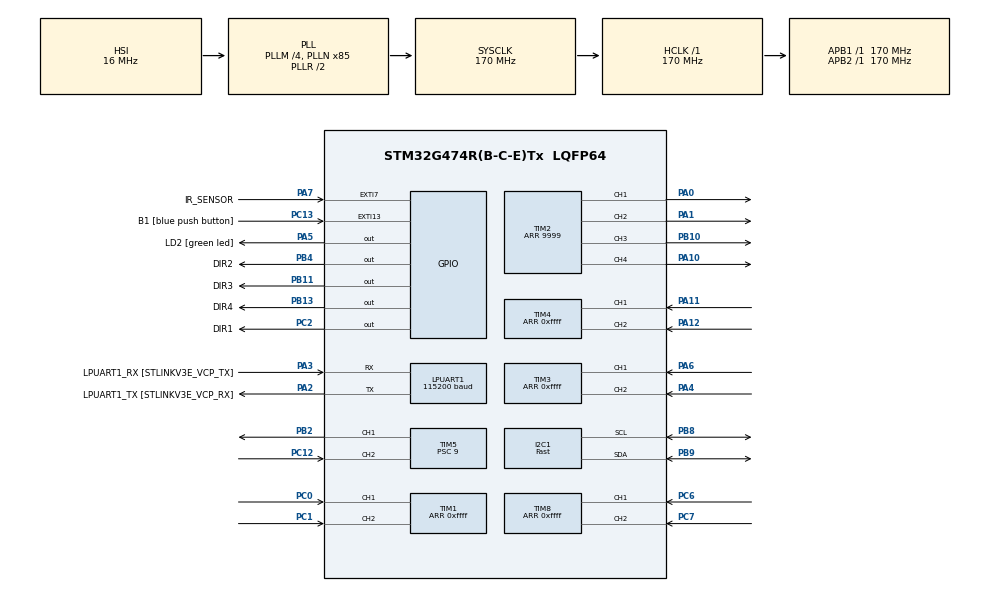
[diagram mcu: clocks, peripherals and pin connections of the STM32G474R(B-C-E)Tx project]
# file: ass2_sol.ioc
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I2C1.I2C_Speed_Mode=I2C_Fast
I2C1.Timing=0x40621236
LPUART1.BaudRate=115200
Mcu.Family=STM32G4
Mcu.Name=STM32G474R(B-C-E)Tx
Mcu.Package=LQFP64
NVIC.EXTI15_10_IRQn=true\:0\:0\:false\:false\:true\:true\:true\:true
NVIC.EXTI9_5_IRQn=true\:0\:0\:false\:false\:true\:true\:true\:true
NVIC.PriorityGroup=NVIC_PRIORITYGROUP_4
NVIC.TIM2_IRQn=true\:0\:0\:false\:false\:true\:true\:true\:true
NVIC.TIM5_IRQn=true\:0\:0\:false\:false\:true\:true\:true\:true
NVIC.TIM6_DAC_IRQn=true\:0\:0\:false\:false\:true\:true\:true\:true
NVIC.TIM7_DAC_IRQn=true\:0\:0\:false\:false\:true\:true\:true\:true
PA0.Signal=S_TIM2_CH1
PA1.Signal=S_TIM2_CH2
PA10.Signal=S_TIM2_CH4
PA11.Signal=S_TIM4_CH1
PA12.Signal=S_TIM4_CH2
PA13.GPIO_Label=T_SWDIO
PA13.Mode=Serial_Wire
PA13.Signal=SYS_JTMS-SWDIO
PA14.GPIO_Label=T_SWCLK
PA14.Mode=Serial_Wire
PA14.Signal=SYS_JTCK-SWCLK
PA2.GPIO_Label=LPUART1_TX [STLINKV3E_VCP_RX]
PA2.Mode=Asynchronous
PA2.Signal=LPUART1_TX
PA3.GPIO_Label=LPUART1_RX [STLINKV3E_VCP_TX]
PA3.Mode=Asynchronous
PA3.Signal=LPUART1_RX
PA4.Signal=S_TIM3_CH2
PA5.GPIO_Label=LD2 [green led]
PA5.Signal=GPIO_Output
PA6.Signal=S_TIM3_CH1
PA7.GPIO_Label=IR_SENSOR
PA7.GPIO_ModeDefaultEXTI=GPIO_MODE_IT_RISING_FALLING
PA7.Signal=GPXTI7
PB10.Signal=S_TIM2_CH3
PB11.GPIO_Label=DIR3
PB11.Signal=GPIO_Output
PB13.GPIO_Label=DIR4
PB13.Signal=GPIO_Output
PB2.Signal=S_TIM5_CH1
PB3.GPIO_Label=T_SWO
PB3.Signal=SYS_JTDO-SWO
PB4.GPIO_Label=DIR2
PB4.Signal=GPIO_Output
PB8-BOOT0.Mode=I2C
PB8-BOOT0.Signal=I2C1_SCL
PB9.Mode=I2C
PB9.Signal=I2C1_SDA
PC0.Signal=S_TIM1_CH1
PC1.Signal=S_TIM1_CH2
PC12.Signal=S_TIM5_CH2
PC13.GPIO_Label=B1 [blue push button]
PC13.Signal=GPXTI13
PC14-OSC32_IN.Mode=LSE-External-Oscillator
PC14-OSC32_IN.Signal=RCC_OSC32_IN
PC15-OSC32_OUT.Mode=LSE-External-Oscillator
PC15-OSC32_OUT.Signal=RCC_OSC32_OUT
PC2.GPIO_Label=DIR1
PC2.Signal=GPIO_Output
PC6.Signal=S_TIM8_CH1
PC7.Signal=S_TIM8_CH2
PF0-OSC_IN.Mode=HSE-External-Oscillator
PF0-OSC_IN.Signal=RCC_OSC_IN
PF1-OSC_OUT.Mode=HSE-External-Oscillator
PF1-OSC_OUT.Signal=RCC_OSC_OUT
ProjectManager.HeapSize=0x200
ProjectManager.StackSize=0x400
ProjectManager.TargetToolchain=STM32CubeIDE
RCC.ADC12Freq_Value=170000000
RCC.ADC345Freq_Value=170000000
RCC.AHBFreq_Value=170000000
RCC.APB1Freq_Value=170000000
RCC.APB1TimFreq_Value=170000000
RCC.APB2Freq_Value=170000000
RCC.APB2TimFreq_Value=170000000
RCC.CortexFreq_Value=170000000
RCC.EXTERNAL_CLOCK_VALUE=12288000
RCC.HCLKFreq_Value=170000000
RCC.HSE_VALUE=24000000
RCC.HSI48_VALUE=48000000
RCC.HSI_VALUE=16000000
RCC.PLLM=RCC_PLLM_DIV4
RCC.PLLN=85
RCC.RTCClockSelection=RCC_RTCCLKSOURCE_LSE
RCC.SYSCLKFreq_VALUE=170000000
RCC.SYSCLKSource=RCC_SYSCLKSOURCE_PLLCLK
RCC.USBFreq_Value=170000000
RCC.VCOOutputFreq_Value=340000000
SH.S_TIM1_CH1.0=TIM1_CH1,Encoder_Interface
SH.S_TIM1_CH2.0=TIM1_CH2,Encoder_Interface
SH.S_TIM2_CH1.0=TIM2_CH1,PWM Generation1 CH1
SH.S_TIM2_CH2.0=TIM2_CH2,PWM Generation2 CH2
SH.S_TIM2_CH3.0=TIM2_CH3,PWM Generation3 CH3
SH.S_TIM2_CH4.0=TIM2_CH4,PWM Generation4 CH4
SH.S_TIM3_CH1.0=TIM3_CH1,Encoder_Interface
SH.S_TIM3_CH2.0=TIM3_CH2,Encoder_Interface
SH.S_TIM4_CH1.0=TIM4_CH1,Encoder_Interface
SH.S_TIM4_CH2.0=TIM4_CH2,Encoder_Interface
SH.S_TIM5_CH1.0=TIM5_CH1,PWM Generation1 CH1
SH.S_TIM5_CH2.0=TIM5_CH2,Input_Capture2_from_TI2
SH.S_TIM8_CH1.0=TIM8_CH1,Encoder_Interface
SH.S_TIM8_CH2.0=TIM8_CH2,Encoder_Interface
TIM1.PeriodNoDither=0xffff
TIM2.Channel-PWM\ Generation1\ CH1=TIM_CHANNEL_1
TIM2.Channel-PWM\ Generation2\ CH2=TIM_CHANNEL_2
TIM2.Channel-PWM\ Generation3\ CH3=TIM_CHANNEL_3
TIM2.Channel-PWM\ Generation4\ CH4=TIM_CHANNEL_4
TIM2.PeriodNoDither=9999
TIM3.PeriodNoDither=0xffff
TIM4.PeriodNoDither=0xffff
TIM5.Channel-Input_Capture2_from_TI2=TIM_CHANNEL_2
TIM5.Channel-PWM\ Generation1\ CH1=TIM_CHANNEL_1
TIM5.ICPolarity_CH2=TIM_INPUTCHANNELPOLARITY_BOTHEDGE
TIM5.PeriodNoDither=1699999
TIM5.Prescaler=9
TIM5.Pulse-PWM\ Generation1\ CH1=170
TIM6.Period=9999
TIM6.Prescaler=169
TIM7.Period=99
TIM7.Prescaler=169
TIM8.PeriodNoDither=0xffff
VP_SYS_VS_DBSignals.Mode=DisableDeadBatterySignals
VP_TIM2_VS_ClockSourceINT.Mode=Internal
VP_TIM5_VS_ClockSourceINT.Mode=Internal
VP_TIM6_VS_ClockSourceINT.Mode=Enable_Timer
VP_TIM7_VS_ClockSourceINT.Mode=Enable_Timer
board=NUCLEO-G474RE

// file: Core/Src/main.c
/* USER CODE BEGIN Header */
/**
  ******************************************************************************
  * @file           : main.c
  * @brief          : Main program body
  ******************************************************************************
  * @attention
  *
  * Copyright (c) 2026 STMicroelectronics.
  * All rights reserved.
  *
  * This software is licensed under terms that can be found in the LICENSE file
  * in the root directory of this software component.
  * If no LICENSE file comes with this software, it is provided AS-IS.
  *
  ******************************************************************************
  */
/* USER CODE END Header */
#include "main.h"

/* USER CODE BEGIN Includes */
#include <stdio.h>
#include "io_board.h"
#include "sonar.h"
#include "ass2.h"
/* USER CODE END Includes */

I2C_HandleTypeDef hi2c1;

UART_HandleTypeDef hlpuart1;

TIM_HandleTypeDef htim1;
TIM_HandleTypeDef htim2;
TIM_HandleTypeDef htim3;
TIM_HandleTypeDef htim4;
TIM_HandleTypeDef htim5;
TIM_HandleTypeDef htim6;
TIM_HandleTypeDef htim7;
TIM_HandleTypeDef htim8;

/* USER CODE BEGIN PV */
volatile uint16_t task = 0;   /* the task that runs: change it in Live Expressions */
/* USER CODE END PV */

void SystemClock_Config(void);
static void MX_GPIO_Init(void);
static void MX_I2C1_Init(void);
static void MX_LPUART1_UART_Init(void);
static void MX_TIM1_Init(void);
static void MX_TIM2_Init(void);
static void MX_TIM3_Init(void);
static void MX_TIM4_Init(void);
static void MX_TIM5_Init(void);
static void MX_TIM6_Init(void);
static void MX_TIM7_Init(void);
static void MX_TIM8_Init(void);

/* USER CODE BEGIN 0 */
/* printf -> LPUART1 (ST-LINK virtual COM port), as in tutorial 2:
   _write() in syscalls.c calls this once per character             */
int __io_putchar(int ch)
{
  HAL_UART_Transmit(&hlpuart1, (uint8_t *)&ch, 1, HAL_MAX_DELAY);
  return ch;
}
/* USER CODE END 0 */

int main(void)
{

  /* MCU Configuration--------------------------------------------------------*/

  /* Reset of all peripherals, Initializes the Flash interface and the Systick. */
  HAL_Init();

  /* Configure the system clock */
  SystemClock_Config();

  /* Initialize all configured peripherals */
  MX_GPIO_Init();
  MX_I2C1_Init();
  MX_LPUART1_UART_Init();
  MX_TIM1_Init();
  MX_TIM2_Init();
  MX_TIM3_Init();
  MX_TIM4_Init();
  MX_TIM5_Init();
  MX_TIM6_Init();
  MX_TIM7_Init();
  MX_TIM8_Init();
  /* USER CODE BEGIN 2 */
  ass2Init();       /* IO board, motor PWM at 0, IR interrupt off, menu */
  /* USER CODE END 2 */

  /* Infinite loop */
  while (1)
  {

    /* USER CODE BEGIN 3 */
    ass2Run();        /* runs the task chosen in `task` until it changes */
  }
  /* USER CODE END 3 */
}

void SystemClock_Config(void)
{
  RCC_OscInitTypeDef RCC_OscInitStruct = {0};
  RCC_ClkInitTypeDef RCC_ClkInitStruct = {0};

  /** Configure the main internal regulator output voltage
  */
  HAL_PWREx_ControlVoltageScaling(PWR_REGULATOR_VOLTAGE_SCALE1_BOOST);

  /** Initializes the RCC Oscillators according to the specified parameters
  * in the RCC_OscInitTypeDef structure.
  */
  RCC_OscInitStruct.OscillatorType = RCC_OSCILLATORTYPE_HSI;
  RCC_OscInitStruct.HSIState = RCC_HSI_ON;
  RCC_OscInitStruct.HSICalibrationValue = RCC_HSICALIBRATION_DEFAULT;
  RCC_OscInitStruct.PLL.PLLState = RCC_PLL_ON;
  RCC_OscInitStruct.PLL.PLLSource = RCC_PLLSOURCE_HSI;
  RCC_OscInitStruct.PLL.PLLM = RCC_PLLM_DIV4;
  RCC_OscInitStruct.PLL.PLLN = 85;
  RCC_OscInitStruct.PLL.PLLP = RCC_PLLP_DIV2;
  RCC_OscInitStruct.PLL.PLLQ = RCC_PLLQ_DIV2;
  RCC_OscInitStruct.PLL.PLLR = RCC_PLLR_DIV2;
  if (HAL_RCC_OscConfig(&RCC_OscInitStruct) != HAL_OK)
  {
    Error_Handler();
  }

  /** Initializes the CPU, AHB and APB buses clocks
  */
  RCC_ClkInitStruct.ClockType = RCC_CLOCKTYPE_HCLK|RCC_CLOCKTYPE_SYSCLK
                              |RCC_CLOCKTYPE_PCLK1|RCC_CLOCKTYPE_PCLK2;
  RCC_ClkInitStruct.SYSCLKSource = RCC_SYSCLKSOURCE_PLLCLK;
  RCC_ClkInitStruct.AHBCLKDivider = RCC_SYSCLK_DIV1;
  RCC_ClkInitStruct.APB1CLKDivider = RCC_HCLK_DIV1;
  RCC_ClkInitStruct.APB2CLKDivider = RCC_HCLK_DIV1;

  if (HAL_RCC_ClockConfig(&RCC_ClkInitStruct, FLASH_LATENCY_4) != HAL_OK)
  {
    Error_Handler();
  }
}

static void MX_I2C1_Init(void)
{

  hi2c1.Instance = I2C1;
  hi2c1.Init.Timing = 0x40621236;
  hi2c1.Init.OwnAddress1 = 0;
  hi2c1.Init.AddressingMode = I2C_ADDRESSINGMODE_7BIT;
  hi2c1.Init.DualAddressMode = I2C_DUALADDRESS_DISABLE;
  hi2c1.Init.OwnAddress2 = 0;
  hi2c1.Init.OwnAddress2Masks = I2C_OA2_NOMASK;
  hi2c1.Init.GeneralCallMode = I2C_GENERALCALL_DISABLE;
  hi2c1.Init.NoStretchMode = I2C_NOSTRETCH_DISABLE;
  if (HAL_I2C_Init(&hi2c1) != HAL_OK)
  {
    Error_Handler();
  }

  /** Configure Analogue filter
  */
  if (HAL_I2CEx_ConfigAnalogFilter(&hi2c1, I2C_ANALOGFILTER_ENABLE) != HAL_OK)
  {
    Error_Handler();
  }

  /** Configure Digital filter
  */
  if (HAL_I2CEx_ConfigDigitalFilter(&hi2c1, 0) != HAL_OK)
  {
    Error_Handler();
  }

}

static void MX_LPUART1_UART_Init(void)
{

  hlpuart1.Instance = LPUART1;
  hlpuart1.Init.BaudRate = 115200;
  hlpuart1.Init.WordLength = UART_WORDLENGTH_8B;
  hlpuart1.Init.StopBits = UART_STOPBITS_1;
  hlpuart1.Init.Parity = UART_PARITY_NONE;
  hlpuart1.Init.Mode = UART_MODE_TX_RX;
  hlpuart1.Init.HwFlowCtl = UART_HWCONTROL_NONE;
  hlpuart1.Init.OneBitSampling = UART_ONE_BIT_SAMPLE_DISABLE;
  hlpuart1.Init.ClockPrescaler = UART_PRESCALER_DIV1;
  hlpuart1.AdvancedInit.AdvFeatureInit = UART_ADVFEATURE_NO_INIT;
  if (HAL_UART_Init(&hlpuart1) != HAL_OK)
  {
    Error_Handler();
  }
  if (HAL_UARTEx_SetTxFifoThreshold(&hlpuart1, UART_TXFIFO_THRESHOLD_1_8) != HAL_OK)
  {
    Error_Handler();
  }
  if (HAL_UARTEx_SetRxFifoThreshold(&hlpuart1, UART_RXFIFO_THRESHOLD_1_8) != HAL_OK)
  {
    Error_Handler();
  }
  if (HAL_UARTEx_DisableFifoMode(&hlpuart1) != HAL_OK)
  {
    Error_Handler();
  }

}

static void MX_TIM1_Init(void)
{

  TIM_Encoder_InitTypeDef sConfig = {0};
  TIM_MasterConfigTypeDef sMasterConfig = {0};

  htim1.Instance = TIM1;
  htim1.Init.Prescaler = 0;
  htim1.Init.CounterMode = TIM_COUNTERMODE_UP;
  htim1.Init.Period = 65535;
  htim1.Init.ClockDivision = TIM_CLOCKDIVISION_DIV1;
  htim1.Init.RepetitionCounter = 0;
  htim1.Init.AutoReloadPreload = TIM_AUTORELOAD_PRELOAD_DISABLE;
  sConfig.EncoderMode = TIM_ENCODERMODE_TI1;
  sConfig.IC1Polarity = TIM_ICPOLARITY_RISING;
  sConfig.IC1Selection = TIM_ICSELECTION_DIRECTTI;
  sConfig.IC1Prescaler = TIM_ICPSC_DIV1;
  sConfig.IC1Filter = 0;
  sConfig.IC2Polarity = TIM_ICPOLARITY_RISING;
  sConfig.IC2Selection = TIM_ICSELECTION_DIRECTTI;
  sConfig.IC2Prescaler = TIM_ICPSC_DIV1;
  sConfig.IC2Filter = 0;
  if (HAL_TIM_Encoder_Init(&htim1, &sConfig) != HAL_OK)
  {
    Error_Handler();
  }
  sMasterConfig.MasterOutputTrigger = TIM_TRGO_RESET;
  sMasterConfig.MasterOutputTrigger2 = TIM_TRGO2_RESET;
  sMasterConfig.MasterSlaveMode = TIM_MASTERSLAVEMODE_DISABLE;
  if (HAL_TIMEx_MasterConfigSynchronization(&htim1, &sMasterConfig) != HAL_OK)
  {
    Error_Handler();
  }

}

static void MX_TIM2_Init(void)
{

  TIM_ClockConfigTypeDef sClockSourceConfig = {0};
  TIM_MasterConfigTypeDef sMasterConfig = {0};
  TIM_OC_InitTypeDef sConfigOC = {0};

  htim2.Instance = TIM2;
  htim2.Init.Prescaler = 0;
  htim2.Init.CounterMode = TIM_COUNTERMODE_UP;
  htim2.Init.Period = 9999;
  htim2.Init.ClockDivision = TIM_CLOCKDIVISION_DIV1;
  htim2.Init.AutoReloadPreload = TIM_AUTORELOAD_PRELOAD_DISABLE;
  if (HAL_TIM_Base_Init(&htim2) != HAL_OK)
  {
    Error_Handler();
  }
  sClockSourceConfig.ClockSource = TIM_CLOCKSOURCE_INTERNAL;
  if (HAL_TIM_ConfigClockSource(&htim2, &sClockSourceConfig) != HAL_OK)
  {
    Error_Handler();
  }
  if (HAL_TIM_PWM_Init(&htim2) != HAL_OK)
  {
    Error_Handler();
  }
  sMasterConfig.MasterOutputTrigger = TIM_TRGO_RESET;
  sMasterConfig.MasterSlaveMode = TIM_MASTERSLAVEMODE_DISABLE;
  if (HAL_TIMEx_MasterConfigSynchronization(&htim2, &sMasterConfig) != HAL_OK)
  {
    Error_Handler();
  }
  sConfigOC.OCMode = TIM_OCMODE_PWM1;
  sConfigOC.Pulse = 0;
  sConfigOC.OCPolarity = TIM_OCPOLARITY_HIGH;
  sConfigOC.OCFastMode = TIM_OCFAST_DISABLE;
  if (HAL_TIM_PWM_ConfigChannel(&htim2, &sConfigOC, TIM_CHANNEL_1) != HAL_OK)
  {
    Error_Handler();
  }
  if (HAL_TIM_PWM_ConfigChannel(&htim2, &sConfigOC, TIM_CHANNEL_2) != HAL_OK)
  {
    Error_Handler();
  }
  if (HAL_TIM_PWM_ConfigChannel(&htim2, &sConfigOC, TIM_CHANNEL_3) != HAL_OK)
  {
    Error_Handler();
  }
  if (HAL_TIM_PWM_ConfigChannel(&htim2, &sConfigOC, TIM_CHANNEL_4) != HAL_OK)
  {
    Error_Handler();
  }
  HAL_TIM_MspPostInit(&htim2);

}

static void MX_TIM3_Init(void)
{

  TIM_Encoder_InitTypeDef sConfig = {0};
  TIM_MasterConfigTypeDef sMasterConfig = {0};

  htim3.Instance = TIM3;
  htim3.Init.Prescaler = 0;
  htim3.Init.CounterMode = TIM_COUNTERMODE_UP;
  htim3.Init.Period = 65535;
  htim3.Init.ClockDivision = TIM_CLOCKDIVISION_DIV1;
  htim3.Init.AutoReloadPreload = TIM_AUTORELOAD_PRELOAD_DISABLE;
  sConfig.EncoderMode = TIM_ENCODERMODE_TI1;
  sConfig.IC1Polarity = TIM_ICPOLARITY_RISING;
  sConfig.IC1Selection = TIM_ICSELECTION_DIRECTTI;
  sConfig.IC1Prescaler = TIM_ICPSC_DIV1;
  sConfig.IC1Filter = 0;
  sConfig.IC2Polarity = TIM_ICPOLARITY_RISING;
  sConfig.IC2Selection = TIM_ICSELECTION_DIRECTTI;
  sConfig.IC2Prescaler = TIM_ICPSC_DIV1;
  sConfig.IC2Filter = 0;
  if (HAL_TIM_Encoder_Init(&htim3, &sConfig) != HAL_OK)
  {
    Error_Handler();
  }
  sMasterConfig.MasterOutputTrigger = TIM_TRGO_RESET;
  sMasterConfig.MasterSlaveMode = TIM_MASTERSLAVEMODE_DISABLE;
  if (HAL_TIMEx_MasterConfigSynchronization(&htim3, &sMasterConfig) != HAL_OK)
  {
    Error_Handler();
  }

}

static void MX_TIM4_Init(void)
{

  TIM_Encoder_InitTypeDef sConfig = {0};
  TIM_MasterConfigTypeDef sMasterConfig = {0};

  htim4.Instance = TIM4;
  htim4.Init.Prescaler = 0;
  htim4.Init.CounterMode = TIM_COUNTERMODE_UP;
  htim4.Init.Period = 65535;
  htim4.Init.ClockDivision = TIM_CLOCKDIVISION_DIV1;
  htim4.Init.AutoReloadPreload = TIM_AUTORELOAD_PRELOAD_DISABLE;
  sConfig.EncoderMode = TIM_ENCODERMODE_TI1;
  sConfig.IC1Polarity = TIM_ICPOLARITY_RISING;
  sConfig.IC1Selection = TIM_ICSELECTION_DIRECTTI;
  sConfig.IC1Prescaler = TIM_ICPSC_DIV1;
  sConfig.IC1Filter = 0;
  sConfig.IC2Polarity = TIM_ICPOLARITY_RISING;
  sConfig.IC2Selection = TIM_ICSELECTION_DIRECTTI;
  sConfig.IC2Prescaler = TIM_ICPSC_DIV1;
  sConfig.IC2Filter = 0;
  if (HAL_TIM_Encoder_Init(&htim4, &sConfig) != HAL_OK)
  {
    Error_Handler();
  }
  sMasterConfig.MasterOutputTrigger = TIM_TRGO_RESET;
  sMasterConfig.MasterSlaveMode = TIM_MASTERSLAVEMODE_DISABLE;
  if (HAL_TIMEx_MasterConfigSynchronization(&htim4, &sMasterConfig) != HAL_OK)
  {
    Error_Handler();
  }

}

static void MX_TIM5_Init(void)
{

  TIM_ClockConfigTypeDef sClockSourceConfig = {0};
  TIM_MasterConfigTypeDef sMasterConfig = {0};
  TIM_OC_InitTypeDef sConfigOC = {0};
  TIM_IC_InitTypeDef sConfigIC = {0};

  htim5.Instance = TIM5;
  htim5.Init.Prescaler = 9;
  htim5.Init.CounterMode = TIM_COUNTERMODE_UP;
  htim5.Init.Period = 1699999;
  htim5.Init.ClockDivision = TIM_CLOCKDIVISION_DIV1;
  htim5.Init.AutoReloadPreload = TIM_AUTORELOAD_PRELOAD_DISABLE;
  if (HAL_TIM_Base_Init(&htim5) != HAL_OK)
  {
    Error_Handler();
  }
  sClockSourceConfig.ClockSource = TIM_CLOCKSOURCE_INTERNAL;
  if (HAL_TIM_ConfigClockSource(&htim5, &sClockSourceConfig) != HAL_OK)
  {
    Error_Handler();
  }
  if (HAL_TIM_PWM_Init(&htim5) != HAL_OK)
  {
    Error_Handler();
  }
  if (HAL_TIM_IC_Init(&htim5) != HAL_OK)
  {
    Error_Handler();
  }
  sMasterConfig.MasterOutputTrigger = TIM_TRGO_RESET;
  sMasterConfig.MasterSlaveMode = TIM_MASTERSLAVEMODE_DISABLE;
  if (HAL_TIMEx_MasterConfigSynchronization(&htim5, &sMasterConfig) != HAL_OK)
  {
    Error_Handler();
  }
  sConfigOC.OCMode = TIM_OCMODE_PWM1;
  sConfigOC.Pulse = 0;
  sConfigOC.OCPolarity = TIM_OCPOLARITY_HIGH;
  sConfigOC.OCFastMode = TIM_OCFAST_DISABLE;
  if (HAL_TIM_PWM_ConfigChannel(&htim5, &sConfigOC, TIM_CHANNEL_1) != HAL_OK)
  {
    Error_Handler();
  }
  sConfigIC.ICPolarity = TIM_INPUTCHANNELPOLARITY_BOTHEDGE;
  sConfigIC.ICSelection = TIM_ICSELECTION_DIRECTTI;
  sConfigIC.ICPrescaler = TIM_ICPSC_DIV1;
  sConfigIC.ICFilter = 0;
  if (HAL_TIM_IC_ConfigChannel(&htim5, &sConfigIC, TIM_CHANNEL_2) != HAL_OK)
  {
    Error_Handler();
  }
  HAL_TIM_MspPostInit(&htim5);

}

static void MX_TIM6_Init(void)
{

  TIM_MasterConfigTypeDef sMasterConfig = {0};

  htim6.Instance = TIM6;
  htim6.Init.Prescaler = 169;
  htim6.Init.CounterMode = TIM_COUNTERMODE_UP;
  htim6.Init.Period = 9999;
  htim6.Init.AutoReloadPreload = TIM_AUTORELOAD_PRELOAD_DISABLE;
  if (HAL_TIM_Base_Init(&htim6) != HAL_OK)
  {
    Error_Handler();
  }
  sMasterConfig.MasterOutputTrigger = TIM_TRGO_RESET;
  sMasterConfig.MasterSlaveMode = TIM_MASTERSLAVEMODE_DISABLE;
  if (HAL_TIMEx_MasterConfigSynchronization(&htim6, &sMasterConfig) != HAL_OK)
  {
    Error_Handler();
  }

}

static void MX_TIM7_Init(void)
{

  TIM_MasterConfigTypeDef sMasterConfig = {0};

  htim7.Instance = TIM7;
  htim7.Init.Prescaler = 169;
  htim7.Init.CounterMode = TIM_COUNTERMODE_UP;
  htim7.Init.Period = 99;
  htim7.Init.AutoReloadPreload = TIM_AUTORELOAD_PRELOAD_DISABLE;
  if (HAL_TIM_Base_Init(&htim7) != HAL_OK)
  {
    Error_Handler();
  }
  sMasterConfig.MasterOutputTrigger = TIM_TRGO_RESET;
  sMasterConfig.MasterSlaveMode = TIM_MASTERSLAVEMODE_DISABLE;
  if (HAL_TIMEx_MasterConfigSynchronization(&htim7, &sMasterConfig) != HAL_OK)
  {
    Error_Handler();
  }

}

static void MX_TIM8_Init(void)
{

  TIM_Encoder_InitTypeDef sConfig = {0};
  TIM_MasterConfigTypeDef sMasterConfig = {0};

  htim8.Instance = TIM8;
  htim8.Init.Prescaler = 0;
  htim8.Init.CounterMode = TIM_COUNTERMODE_UP;
  htim8.Init.Period = 65535;
  htim8.Init.ClockDivision = TIM_CLOCKDIVISION_DIV1;
  htim8.Init.RepetitionCounter = 0;
  htim8.Init.AutoReloadPreload = TIM_AUTORELOAD_PRELOAD_DISABLE;
  sConfig.EncoderMode = TIM_ENCODERMODE_TI1;
  sConfig.IC1Polarity = TIM_ICPOLARITY_RISING;
  sConfig.IC1Selection = TIM_ICSELECTION_DIRECTTI;
  sConfig.IC1Prescaler = TIM_ICPSC_DIV1;
  sConfig.IC1Filter = 0;
  sConfig.IC2Polarity = TIM_ICPOLARITY_RISING;
  sConfig.IC2Selection = TIM_ICSELECTION_DIRECTTI;
  sConfig.IC2Prescaler = TIM_ICPSC_DIV1;
  sConfig.IC2Filter = 0;
  if (HAL_TIM_Encoder_Init(&htim8, &sConfig) != HAL_OK)
  {
    Error_Handler();
  }
  sMasterConfig.MasterOutputTrigger = TIM_TRGO_RESET;
  sMasterConfig.MasterOutputTrigger2 = TIM_TRGO2_RESET;
  sMasterConfig.MasterSlaveMode = TIM_MASTERSLAVEMODE_DISABLE;
  if (HAL_TIMEx_MasterConfigSynchronization(&htim8, &sMasterConfig) != HAL_OK)
  {
    Error_Handler();
  }

}

static void MX_GPIO_Init(void)
{
  GPIO_InitTypeDef GPIO_InitStruct = {0};

  /* GPIO Ports Clock Enable */
  __HAL_RCC_GPIOC_CLK_ENABLE();
  __HAL_RCC_GPIOF_CLK_ENABLE();
  __HAL_RCC_GPIOA_CLK_ENABLE();
  __HAL_RCC_GPIOB_CLK_ENABLE();

  /*Configure GPIO pin Output Level */
  HAL_GPIO_WritePin(DIR1_GPIO_Port, DIR1_Pin, GPIO_PIN_RESET);

  /*Configure GPIO pin Output Level */
  HAL_GPIO_WritePin(LD2_GPIO_Port, LD2_Pin, GPIO_PIN_RESET);

  /*Configure GPIO pin Output Level */
  HAL_GPIO_WritePin(GPIOB, DIR3_Pin|DIR4_Pin|DIR2_Pin, GPIO_PIN_RESET);

  /*Configure GPIO pin : B1_Pin */
  GPIO_InitStruct.Pin = B1_Pin;
  GPIO_InitStruct.Mode = GPIO_MODE_IT_RISING;
  GPIO_InitStruct.Pull = GPIO_NOPULL;
  HAL_GPIO_Init(B1_GPIO_Port, &GPIO_InitStruct);

  /*Configure GPIO pin : DIR1_Pin */
  GPIO_InitStruct.Pin = DIR1_Pin;
  GPIO_InitStruct.Mode = GPIO_MODE_OUTPUT_PP;
  GPIO_InitStruct.Pull = GPIO_NOPULL;
  GPIO_InitStruct.Speed = GPIO_SPEED_FREQ_LOW;
  HAL_GPIO_Init(DIR1_GPIO_Port, &GPIO_InitStruct);

  /*Configure GPIO pin : LD2_Pin */
  GPIO_InitStruct.Pin = LD2_Pin;
  GPIO_InitStruct.Mode = GPIO_MODE_OUTPUT_PP;
  GPIO_InitStruct.Pull = GPIO_NOPULL;
  GPIO_InitStruct.Speed = GPIO_SPEED_FREQ_LOW;
  HAL_GPIO_Init(LD2_GPIO_Port, &GPIO_InitStruct);

  /*Configure GPIO pin : IR_SENSOR_Pin */
  GPIO_InitStruct.Pin = IR_SENSOR_Pin;
  GPIO_InitStruct.Mode = GPIO_MODE_IT_RISING_FALLING;
  GPIO_InitStruct.Pull = GPIO_NOPULL;
  HAL_GPIO_Init(IR_SENSOR_GPIO_Port, &GPIO_InitStruct);

  /*Configure GPIO pins : DIR3_Pin DIR4_Pin DIR2_Pin */
  GPIO_InitStruct.Pin = DIR3_Pin|DIR4_Pin|DIR2_Pin;
  GPIO_InitStruct.Mode = GPIO_MODE_OUTPUT_PP;
  GPIO_InitStruct.Pull = GPIO_NOPULL;
  GPIO_InitStruct.Speed = GPIO_SPEED_FREQ_LOW;
  HAL_GPIO_Init(GPIOB, &GPIO_InitStruct);

  /* EXTI interrupt init*/
  HAL_NVIC_SetPriority(EXTI9_5_IRQn, 0, 0);
  HAL_NVIC_EnableIRQ(EXTI9_5_IRQn);

  HAL_NVIC_SetPriority(EXTI15_10_IRQn, 0, 0);
  HAL_NVIC_EnableIRQ(EXTI15_10_IRQn);

}

void Error_Handler(void)
{
  __disable_irq();
  while (1)
  {
  }
}
